AUTOSAR XML (schema 4-0-3)
package /ComponentTypes
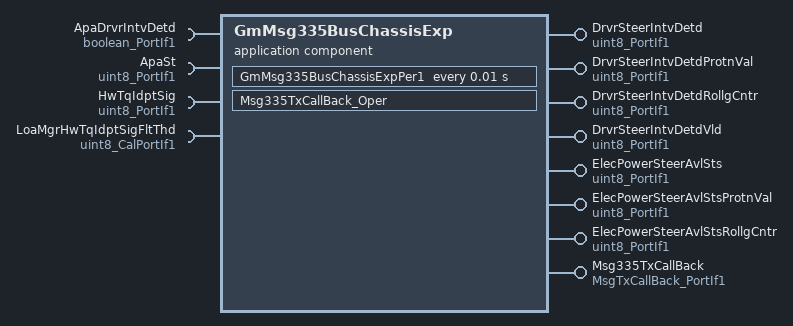
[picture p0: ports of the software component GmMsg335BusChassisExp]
  application sw component type GmMsg335BusChassisExp
    8 x provide port:
      DrvrSteerIntvDetd: nonqueued-sender-com-spec{data-element=Val, init-value=0}, provided-interface=uint8_PortIf1
      DrvrSteerIntvDetdProtnVal: nonqueued-sender-com-spec{data-element=Val, init-value=0}, provided-interface=uint8_PortIf1
      DrvrSteerIntvDetdRollgCntr: nonqueued-sender-com-spec{data-element=Val, init-value=0}, provided-interface=uint8_PortIf1
      DrvrSteerIntvDetdVld: nonqueued-sender-com-spec{data-element=Val, init-value=0}, provided-interface=uint8_PortIf1
      ElecPowerSteerAvlSts: nonqueued-sender-com-spec{data-element=Val, init-value=0}, provided-interface=uint8_PortIf1
      ElecPowerSteerAvlStsProtnVal: nonqueued-sender-com-spec{data-element=Val, init-value=0}, provided-interface=uint8_PortIf1
      ElecPowerSteerAvlStsRollgCntr: nonqueued-sender-com-spec{data-element=Val, init-value=0}, provided-interface=uint8_PortIf1
      Msg335TxCallBack: server-com-spec{operation=Oper, queue-length=1}, provided-interface=MsgTxCallBack_PortIf1
    4 x require port:
      ApaDrvrIntvDetd: nonqueued-receiver-com-spec{data-element=Logl, filter=data-filter-type=ALWAYS, init-value=0}, required-interface=boolean_PortIf1
      ApaSt: nonqueued-receiver-com-spec{data-element=Val, filter=data-filter-type=ALWAYS, init-value=0}, required-interface=uint8_PortIf1
      HwTqIdptSig: nonqueued-receiver-com-spec{data-element=Val, filter=data-filter-type=ALWAYS, init-value=4}, required-interface=uint8_PortIf1
      LoaMgrHwTqIdptSigFltThd: parameter-require-com-spec{init-value=1, parameter=Val}, required-interface=uint8_CalPortIf1
    behavior GmMsg335BusChassisExp_InternalBehavior: data-type-mapping=Nexteer
      ar-typed-per-instance-memorys:
        data GmMsg335BusChassisExpRollgCntr: sw-calibration-access=READ-ONLY, type=uint8
      timing event TMT_GM0C9HSPer1: start-on-event=GmMsg335BusChassisExpPer1, period=0.01
      operation invoked event OIT_Msg335TxCallBack_Oper_Msg335TxCallBack_Oper: start-on-event=Msg335TxCallBack_Oper, operation=Msg335TxCallBack.Oper
      runnable GmMsg335BusChassisExpPer1
        data-receive-point-by-arguments:
          access REC_ApaDrvrIntvDetd_Logl: accessed-variable=ApaDrvrIntvDetd.Logl
          access REC_EscSt_Val: accessed-variable=ApaSt.Val
          access REC_HwTqIdptSig_Val: accessed-variable=HwTqIdptSig.Val
        data-send-points:
          7 x access:
            SEND_DrvrSteerIntvDetd_Val: accessed-variable=DrvrSteerIntvDetd.Val
            SEND_DrvrSteerIntvDetdProtnVal_Val: accessed-variable=DrvrSteerIntvDetdProtnVal.Val
            SEND_DrvrSteerIntvDetdRollgCntr_Val: accessed-variable=DrvrSteerIntvDetdRollgCntr.Val
            SEND_DrvrSteerIntvDetdVld_Val: accessed-variable=DrvrSteerIntvDetdVld.Val
            SEND_ElecPowerSteerAvlSts_Val: accessed-variable=ElecPowerSteerAvlSts.Val
            SEND_ElecPowerSteerAvlStsProtnVal_Val: accessed-variable=ElecPowerSteerAvlStsProtnVal.Val
            SEND_ElecPowerSteerAvlStsRollgCntr_Val: accessed-variable=ElecPowerSteerAvlStsRollgCntr.Val
      runnable Msg335TxCallBack_Oper
  swc implementation GmMsg335BusChassisExp_Implementation: behavior=GmMsg335BusChassisExp_InternalBehavior
    code-descriptors:
      code Default: artifact-descriptors=autosar-engineering-object={short-label=Default, category=SWSRC}
